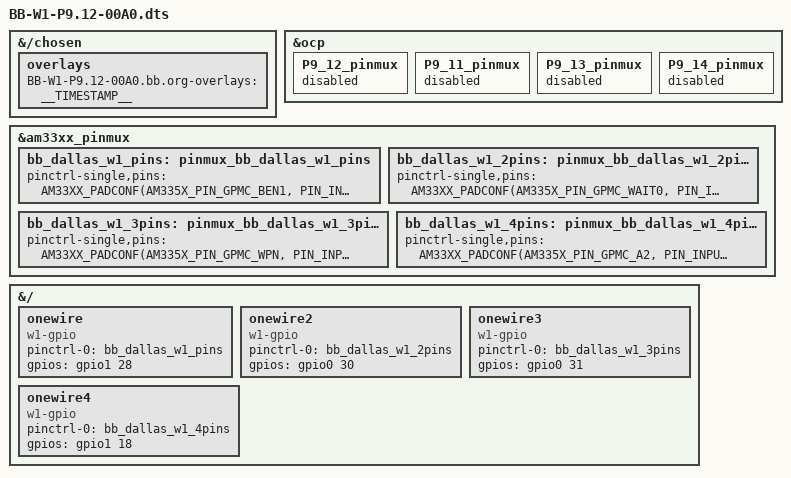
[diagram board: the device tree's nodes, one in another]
// SPDX-License-Identifier: GPL-2.0-only
/*
 * Copyright (C) 2015 Robert Nelson <robertcnelson@gmail.com>
 * Virtual cape for onewire on connector pin P9.12
 */

/dts-v1/;
/plugin/;

#include <dt-bindings/gpio/gpio.h>
#include <dt-bindings/pinctrl/am33xx.h>

/*
 * Helper to show loaded overlays under: /proc/device-tree/chosen/overlays/
 */
&{/chosen} {
	overlays {
		BB-W1-P9.12-00A0.bb.org-overlays = __TIMESTAMP__;
	};
};

/*
 * Free up the pins used by the cape from the pinmux helpers.
 */
&ocp {
        P9_12_pinmux { status = "disabled"; };  /* P9_12 (U18) gpmc_be1n.gpio1_28 */
        P9_11_pinmux { status = "disabled"; };  /* P9_12 (U18) gpmc_be1n.gpio1_28 */
        P9_13_pinmux { status = "disabled"; };  /* P9_12 (U18) gpmc_be1n.gpio1_28 */
	P9_14_pinmux { status = "disabled"; };  /* P9_12 (U18) gpmc_be1n.gpio1_28 */
};

&am33xx_pinmux {
        bb_dallas_w1_pins: pinmux_bb_dallas_w1_pins {
                pinctrl-single,pins = <
                        AM33XX_PADCONF(AM335X_PIN_GPMC_BEN1, PIN_INPUT_PULLUP, MUX_MODE7)       /* P9_12 (U18) gpmc_be1n.gpio1_28 */

                >;
        };
         bb_dallas_w1_2pins: pinmux_bb_dallas_w1_2pins {
                pinctrl-single,pins = <
                        AM33XX_PADCONF(AM335X_PIN_GPMC_WAIT0, PIN_INPUT_PULLUP, MUX_MODE7)       /* P8_27 (U18) gpmc_be1n.gpio1_22 */

                >;
        };
         bb_dallas_w1_3pins: pinmux_bb_dallas_w1_3pins {
                pinctrl-single,pins = <
                        AM33XX_PADCONF(AM335X_PIN_GPMC_WPN, PIN_INPUT_PULLUP, MUX_MODE7)       /* P8_28 (U18) gpmc_be1n.gpio1_24 */

                >;
        };
	 bb_dallas_w1_4pins: pinmux_bb_dallas_w1_4pins {
                pinctrl-single,pins = <
                        AM33XX_PADCONF(AM335X_PIN_GPMC_A2, PIN_INPUT_PULLUP, MUX_MODE7)       /* P8_28 (U18) gpmc_be1n.gpio1_24 */

                >;
        };

};

&{/} {
        onewire {
                status = "okay";
                pinctrl-names = "default";
                pinctrl-0 = <&bb_dallas_w1_pins>;

                compatible = "w1-gpio";
                gpios = <&gpio1 28 GPIO_ACTIVE_HIGH>;
        };
 	onewire2 {
                status = "okay";
                pinctrl-names = "default";
                pinctrl-0 = <&bb_dallas_w1_2pins>;

                compatible = "w1-gpio";
                gpios = <&gpio0 30 GPIO_ACTIVE_HIGH>;
        };
        onewire3 {
                status = "okay";
                pinctrl-names = "default";
                pinctrl-0 = <&bb_dallas_w1_3pins>;

                compatible = "w1-gpio";
                gpios = <&gpio0 31 GPIO_ACTIVE_HIGH>;
        };
	onewire4 {
                status = "okay";
                pinctrl-names = "default";
                pinctrl-0 = <&bb_dallas_w1_4pins>;

                compatible = "w1-gpio";
                gpios = <&gpio1 18 GPIO_ACTIVE_HIGH>;
        };

};
